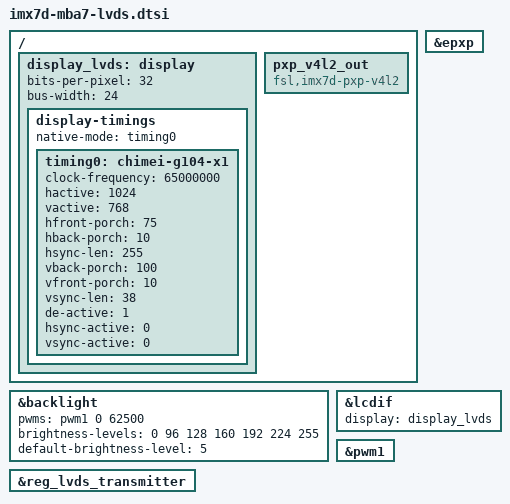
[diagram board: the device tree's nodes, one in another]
/*
 * Copyright (C) 2016 TQ Systems GmbH
 * Author: Marco Felsch <Marco.Felsch@tq-group.com>
 *
 * This file is dual-licensed: you can use it either under the terms
 * of the GPL or the X11 license, at your option. Note that this dual
 * licensing only applies to this file, and not this project as a
 * whole.
 *
 *  a) This file is free software; you can redistribute it and/or
 *     modify it under the terms of the GNU General Public License as
 *     published by the Free Software Foundation; either version 2 of the
 *     License, or (at your option) any later version.
 *
 *     This file is distributed in the hope that it will be useful,
 *     but WITHOUT ANY WARRANTY; without even the implied warranty of
 *     MERCHANTABILITY or FITNESS FOR A PARTICULAR PURPOSE.  See the
 *     GNU General Public License for more details.
 *
 * Or, alternatively,
 *
 *  b) Permission is hereby granted, free of charge, to any person
 *     obtaining a copy of this software and associated documentation
 *     files (the "Software"), to deal in the Software without
 *     restriction, including without limitation the rights to use,
 *     copy, modify, merge, publish, distribute, sublicense, and/or
 *     sell copies of the Software, and to permit persons to whom the
 *     Software is furnished to do so, subject to the following
 *     conditions:
 *
 *     The above copyright notice and this permission notice shall be
 *     included in all copies or substantial portions of the Software.
 *
 *     THE SOFTWARE IS PROVIDED "AS IS", WITHOUT WARRANTY OF ANY KIND,
 *     EXPRESS OR IMPLIED, INCLUDING BUT NOT LIMITED TO THE WARRANTIES
 *     OF MERCHANTABILITY, FITNESS FOR A PARTICULAR PURPOSE AND
 *     NONINFRINGEMENT. IN NO EVENT SHALL THE AUTHORS OR COPYRIGHT
 *     HOLDERS BE LIABLE FOR ANY CLAIM, DAMAGES OR OTHER LIABILITY,
 *     WHETHER IN AN ACTION OF CONTRACT, TORT OR OTHERWISE, ARISING
 *     FROM, OUT OF OR IN CONNECTION WITH THE SOFTWARE OR THE USE OR
 *     OTHER DEALINGS IN THE SOFTWARE.
 */

/ {
	display_lvds: display {
		bits-per-pixel = <32>; /* 32: RGB888/666 mode */
		bus-width = <24>;

		display-timings {
			native-mode = <&timing0>;
			timing0: chimei-g104-x1 {
				clock-frequency = <65000000>;
				hactive = <1024>;
				vactive = <768>;
				hfront-porch = <75>;
				hback-porch = <10>;
				hsync-len = <255>; /* FIXME: typ < 256!*/
				vback-porch = <100>;
				vfront-porch = <10>;
				vsync-len = <38>;
				de-active = <1>;
				hsync-active = <0>;
				vsync-active = <0>;
			};
		};
	};

	pxp_v4l2_out {
		compatible = "fsl,imx7d-pxp-v4l2", "fsl,imx6sx-pxp-v4l2", "fsl,imx6sl-pxp-v4l2";
		status = "okay";
	};
};

&backlight {
	pwms = <&pwm1 0 62500>;
	brightness-levels = <0 96 128 160 192 224 255>;
	default-brightness-level = <5>;
	status = "okay";
};

&epxp {
	status = "okay";
};

&lcdif {
	display = <&display_lvds>;
	status = "okay";
};

&pwm1 {
	status = "okay";
};

&reg_lvds_transmitter {
	status = "okay";
};
